AUTOSAR XML (schema 00049)
package /ComponentTypes
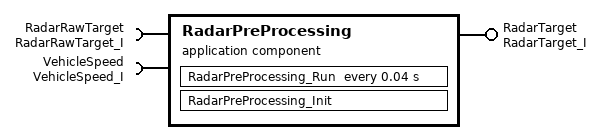
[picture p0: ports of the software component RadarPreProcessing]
  application sw component type RadarPreProcessing
    require port RadarRawTarget: required-interface=RadarRawTarget_I
      required-com-specs:
        data-element=RawDistance, alive-timeout=0.12, handle-never-received=true, init-value=constant-reference=TargetDistance_IV
        data-element=RawRelativeSpeed, alive-timeout=0.12, handle-never-received=true, init-value=constant-reference=RelativeSpeed_IV
        data-element=RawTargetValid, alive-timeout=0.12, handle-never-received=true, init-value=constant-reference=RadarTargetValid_IV
    require port VehicleSpeed: nonqueued-receiver-com-spec{data-element=VehicleSpeed, init-value=constant-reference=VehicleSpeed_IV}, required-interface=VehicleSpeed_I
    provide port RadarTarget: provided-interface=RadarTarget_I
      provided-com-specs:
        data-element=TargetDistance, init-value=constant-reference=TargetDistance_IV
        data-element=TargetRelativeSpeed, init-value=constant-reference=RelativeSpeed_IV
        data-element=TargetValid, init-value=constant-reference=RadarTargetValid_IV
    behavior RadarPreProcessing_InternalBehavior: data-type-mapping=AccTypeMappingSet
      init event IT_RadarPreProcessing_Init: start-on-event=RadarPreProcessing_Init
      timing event TMT_RadarPreProcessing_Run: start-on-event=RadarPreProcessing_Run, period=0.04
      port-api-options:
        enable-take-address=false, indirect-api=false, port=RadarRawTarget
        enable-take-address=false, indirect-api=false, port=RadarTarget
        enable-take-address=false, indirect-api=false, port=VehicleSpeed
      runnable RadarPreProcessing_Init
      runnable RadarPreProcessing_Run
        data-receive-point-by-arguments:
          4 x access:
            REC_RadarRawTarget_RawDistance: accessed-variable=RadarRawTarget.RawDistance
            REC_RadarRawTarget_RawRelativeSpeed: accessed-variable=RadarRawTarget.RawRelativeSpeed
            REC_RadarRawTarget_RawTargetValid: accessed-variable=RadarRawTarget.RawTargetValid
            REC_VehicleSpeed_VehicleSpeed: accessed-variable=VehicleSpeed.VehicleSpeed
        data-send-points:
          access SEND_RadarTarget_TargetDistance: accessed-variable=RadarTarget.TargetDistance
          access SEND_RadarTarget_TargetRelativeSpeed: accessed-variable=RadarTarget.TargetRelativeSpeed
          access SEND_RadarTarget_TargetValid: accessed-variable=RadarTarget.TargetValid
  swc implementation RadarPreProcessing_Implementation: behavior=RadarPreProcessing_InternalBehavior
